# ADSP-SC83xW_HPC register map
Vendor: Analog Devices; Series: ADSP-SC83xW_HPC; File version: 3.0.3.517
CPU: 
Registers are 32-bit, read-write, reset 0x0 unless marked. A register's access mark holds for its fields unless they carry their own. Offsets are from the block's base; [hi:lo] are bit positions; {n}, {i} and the like mark numbered series.

## EMAC0 (part 2 of 4) — RGMII, RMII, MII Ethernet Controller
Base 0x31040000
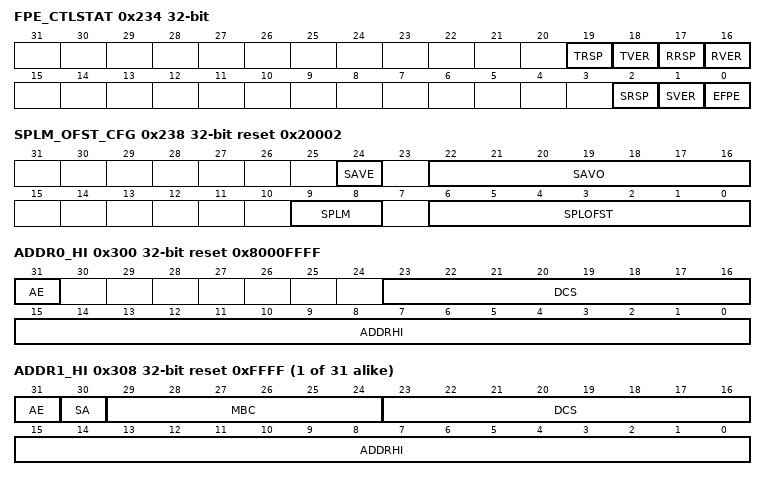
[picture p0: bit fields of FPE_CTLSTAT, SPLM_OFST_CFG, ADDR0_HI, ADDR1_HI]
0x234 FPE_CTLSTAT — Frame Preemption Control and Status Register
  [19] TRSP — Transmitted Respond Frame
    0=TRSP_INACTIVE (Not Transmitted Respond Frame); 1=TRSP_ACTIVE (Transmitted Respond Frame)
  [18] TVER — Transmitted Verify Frame
    0=TVER_INACTIVE (Not Transmitted Verify Frame); 1=TVER_ACTIVE (Transmitted Verify Frame)
  [17] RRSP — Received Respond Frame
    0=RRSP_INACTIVE (Not Received Respond Frame); 1=RRSP_ACTIVE (Received Respond Frame)
  [16] RVER — Received Verify Frame
    0=RVER_INACTIVE (Not Received Verify Frame); 1=RVER_ACTIVE (Received Verify Frame)
  [2] SRSP — Send Respond mPacket
    0=SRSP_DISABLE (Send Respond MPacket is Disabled); 1=SRSP_ENABLE (Send Respond MPacket is Enabled)
  [1] SVER — Send Verify mPacket
    0=SVER_DISABLE (Send Verify MPacket is Disabled); 1=SVER_ENABLE (Send Verify MPacket is Enabled)
  [0] EFPE — Enable Tx Frame Preemption
    0=EFPE_DISABLE (Tx Frame Preemption is Disabled); 1=EFPE_ENABLE (Tx Frame Preemption is Enabled)
0x238 SPLM_OFST_CFG reset 0x20002 — MAC Split Mode and Offset Configuration Register
  [24] SAVE range 0x00000000..0x00000001 — Split AV Enable
  [22:16] SAVO range 0x00000000..0x0000007F — Split AV Offset
  [9:8] SPLM — Split Mode
    0=L3L4 (Split at L3/L4 Header); 1=L2OFST (Split at L2 Header with an Offset. Always Split at SPLOFST Bytes from the Beginning of Length/Type Field of the Frame); 2=COMBN (Combination Mode: Split Similar to SPLM=00 for IP Packets That are Untagged or Tagged and VLAN Stripped)
  [6:0] SPLOFST range 0x00000000..0x0000007F — Split Offset
0x240 PRSNTM_NSEC — Presentation Time Nanosecond Register
  [31:0] MPTN ro — 1722 Presentation Time in Nanoseconds
0x244 PRSNTM_UPDT — Presentation Time Update Register
  [31:0] MPTU range 0x00000000..0xFFFFFFFF — 1722 Presentation Time Update
0x300 ADDR0_HI reset 0x8000FFFF — MAC Address 0 High Register
  [31] AE ro — Address Enable
    0=AE_DISABLE (Invalid); 1=AE_ENABLE (The bit is always set)
  [23:16] DCS range 0x00000000..0x000000FF — DMA Channel Select
  [15:0] ADDRHI range 0x00000000..0x0000FFFF — MAC address 0[47:32]
0x304 ADDR0_LO reset 0xFFFFFFFF — MAC Address 0 Low Register
  [31:0] ADDRLO range 0x00000000..0xFFFFFFFF — MAC Address0[31:0]
{0x300+8i} ADDR{i}_HI reset 0xFFFF (i=1..31) — MAC Address n High Register
  [31] AE — Address Enable
    0=AE_DISABLE (Address is Ignored); 1=AE_ENABLE (Address is Enabled)
  [30] SA — Source Address
    0=DA (Compare with Destination Address); 1=SA (Compare with Source Address)
  [29:24] MBC range 0x00000000..0x0000003F — Mask Byte Control
  [23:16] DCS range 0x00000000..0x000000FF — DMA Channel Select
  [15:0] ADDRHI range 0x00000000..0x0000FFFF — MAC Address1 [47:32]
{0x304+8i} ADDR{i}_LO reset 0xFFFFFFFF (i=1..31) — MAC Address n Low Register
  [31:0] ADDRLO range 0x00000000..0xFFFFFFFF — MAC Address1 [31:0]
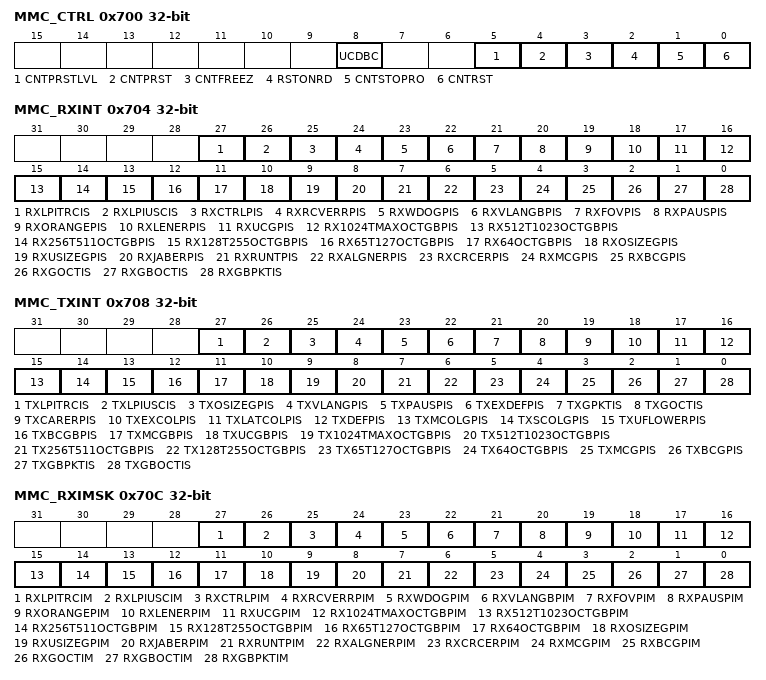
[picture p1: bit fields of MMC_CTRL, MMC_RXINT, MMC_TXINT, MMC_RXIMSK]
0x700 MMC_CTRL — MMC Control Register
  [8] UCDBC — Update MMC Counters for Dropped Broadcast Packets
    0=UCDBC_DISABLE (Update MMC Counters for Dropped Broadcast Packets is Disabled); 1=UCDBC_ENABLE (Update MMC Counters for Dropped Broadcast Packets is Enabled)
  [5] CNTPRSTLVL — Full-Half Preset
    0=CNTPRSTLVL_DISABLE (Full-Half Preset is Disabled); 1=CNTPRSTLVL_ENABLE (Full-Half Preset is Enabled)
  [4] CNTPRST — Counters Preset
    0=CNTPRST_DISABLE (Counters Preset is Disabled); 1=CNTPRST_ENABLE (Counters Preset is Enabled)
  [3] CNTFREEZ — MMC Counter Freeze
    0=CNTFREEZ_DISABLE (MMC Counter Freeze is Disabled); 1=CNTFREEZ_ENABLE (MMC Counter Freeze is Enabled)
  [2] RSTONRD — Reset on Read
    0=RSTONRD_DISABLE (Reset on Read is Disabled); 1=RSTONRD_ENABLE (Reset on Read is Enabled)
  [1] CNTSTOPRO — Counter Stop Rollover
    0=CNTSTOPRO_DISABLE (Counter Stop Rollover is Disabled); 1=CNTSTOPRO_ENABLE (Counter Stop Rollover is Enabled)
  [0] CNTRST — Counters Reset
    0=CNTRST_DISABLE (Counters are Not Reset); 1=CNTRST_ENABLE (All Counters are Reset)
0x704 MMC_RXINT — MMC Receive Interrupt Status Register
  [27] RXLPITRCIS ro — MMC Receive LPI Transition Counter Interrupt Status
    0=RXLPITRCIS_INACTIVE (MMC Receive LPI Transition Counter Interrupt Status Not Detected); 1=RXLPITRCIS_ACTIVE (MMC Receive LPI Transition Counter Interrupt Status Detected)
  [26] RXLPIUSCIS ro — MMC Receive LPI Microsecond Counter Interrupt Status
    0=RXLPIUSCIS_INACTIVE (MMC Receive LPI Microsecond Counter Interrupt Status Not Detected); 1=RXLPIUSCIS_ACTIVE (MMC Receive LPI Microsecond Counter Interrupt Status Detected)
  [25] RXCTRLPIS ro — MMC Receive Control Packet Counter Interrupt Status
    0=RXCTRLPIS_INACTIVE (MMC Receive Control Packet Counter Interrupt Status Not Detected); 1=RXCTRLPIS_ACTIVE (MMC Receive Control Packet Counter Interrupt Status Detected)
  [24] RXRCVERRPIS ro — MMC Receive Error Packet Counter Interrupt Status
    0=RXRCVERRPIS_INACTIVE (MMC Receive Error Packet Counter Interrupt Status Not Detected); 1=RXRCVERRPIS_ACTIVE (MMC Receive Error Packet Counter Interrupt Status Detected)
  [23] RXWDOGPIS ro — MMC Receive Watchdog Error Packet Counter Interrupt Status
    0=RXWDOGPIS_INACTIVE (MMC Receive Watchdog Error Packet Counter Interrupt Status Not Detected); 1=RXWDOGPIS_ACTIVE (MMC Receive Watchdog Error Packet Counter Interrupt Status Detected)
  [22] RXVLANGBPIS ro — MMC Receive VLAN Good Bad Packet Counter Interrupt Status
    0=RXVLANGBPIS_INACTIVE (MMC Receive VLAN Good Bad Packet Counter Interrupt Status Not Detected); 1=RXVLANGBPIS_ACTIVE (MMC Receive VLAN Good Bad Packet Counter Interrupt Status Detected)
  [21] RXFOVPIS ro — MMC Receive FIFO Overflow Packet Counter Interrupt Status
    0=RXFOVPIS_INACTIVE (MMC Receive FIFO Overflow Packet Counter Interrupt Status Not Detected); 1=RXFOVPIS_ACTIVE (MMC Receive FIFO Overflow Packet Counter Interrupt Status Detected)
  [20] RXPAUSPIS ro — MMC Receive Pause Packet Counter Interrupt Status
    0=RXPAUSPIS_INACTIVE (MMC Receive Pause Packet Counter Interrupt Status Not Detected); 1=RXPAUSPIS_ACTIVE (MMC Receive Pause Packet Counter Interrupt Status Detected)
  [19] RXORANGEPIS ro — MMC Receive Out of Range Error Packet Counter Interrupt Status.
    0=RXORANGEPIS_INACTIVE (MMC Receive Out of Range Error Packet Counter Interrupt Status Not Detected); 1=RXORANGEPIS_ACTIVE (MMC Receive Out of Range Error Packet Counter Interrupt Status Detected)
  [18] RXLENERPIS ro — MMC Receive Length Error Packet Counter Interrupt Status
    0=RXLENERPIS_INACTIVE (MMC Receive Length Error Packet Counter Interrupt Status Not Detected); 1=RXLENERPIS_ACTIVE (MMC Receive Length Error Packet Counter Interrupt Status Detected)
  [17] RXUCGPIS ro — MMC Receive Unicast Good Packet Counter Interrupt Status
    0=RXUCGPIS_INACTIVE (MMC Receive Unicast Good Packet Counter Interrupt Status Not Detected); 1=RXUCGPIS_ACTIVE (MMC Receive Unicast Good Packet Counter Interrupt Status Detected)
  [16] RX1024TMAXOCTGBPIS ro — MMC Receive 1024 to Maximum Octet Good Bad Packet Counter Interrupt Status
    0=RX1024TMAXOCTGBPIS_INACTIVE (MMC Receive 1024 to Maximum Octet Good Bad Packet Counter Interrupt Status Not Detected); 1=RX1024TMAXOCTGBPIS_ACTIVE (MMC Receive 1024 to Maximum Octet Good Bad Packet Counter Interrupt Status Detected)
  [15] RX512T1023OCTGBPIS ro — MMC Receive 512 to 1023 Octet Good Bad Packet Counter Interrupt Status
    0=RX512T1023OCTGBPIS_INACTIVE (MMC Receive 512 to 1023 Octet Good Bad Packet Counter Interrupt Status Not Detected); 1=RX512T1023OCTGBPIS_ACTIVE (MMC Receive 512 to 1023 Octet Good Bad Packet Counter Interrupt Status Detected)
  [14] RX256T511OCTGBPIS ro — MMC Receive 256 to 511 Octet Good Bad Packet Counter Interrupt Status
    0=RX256T511OCTGBPIS_INACTIVE (MMC Receive 256 to 511 Octet Good Bad Packet Counter Interrupt Status Not Detected); 1=RX256T511OCTGBPIS_ACTIVE (MMC Receive 256 to 511 Octet Good Bad Packet Counter Interrupt Status Detected)
  [13] RX128T255OCTGBPIS ro — MMC Receive 128 to 255 Octet Good Bad Packet Counter Interrupt Status
    0=RX128T255OCTGBPIS_INACTIVE (MMC Receive 128 to 255 Octet Good Bad Packet Counter Interrupt Status Not Detected); 1=RX128T255OCTGBPIS_ACTIVE (MMC Receive 128 to 255 Octet Good Bad Packet Counter Interrupt Status Detected)
  [12] RX65T127OCTGBPIS ro — MMC Receive 65 to 127 Octet Good Bad Packet Counter Interrupt Status
    0=RX65T127OCTGBPIS_INACTIVE (MMC Receive 65 to 127 Octet Good Bad Packet Counter Interrupt Status Not Detected); 1=RX65T127OCTGBPIS_ACTIVE (MMC Receive 65 to 127 Octet Good Bad Packet Counter Interrupt Status Detected)
  [11] RX64OCTGBPIS ro — MMC Receive 64 Octet Good Bad Packet Counter Interrupt Status
    0=RX64OCTGBPIS_INACTIVE (MMC Receive 64 Octet Good Bad Packet Counter Interrupt Status Not Detected); 1=RX64OCTGBPIS_ACTIVE (MMC Receive 64 Octet Good Bad Packet Counter Interrupt Status Detected)
  [10] RXOSIZEGPIS ro — MMC Receive Oversize Good Packet Counter Interrupt Status
    0=RXOSIZEGPIS_INACTIVE (MMC Receive Oversize Good Packet Counter Interrupt Status Not Detected); 1=RXOSIZEGPIS_ACTIVE (MMC Receive Oversize Good Packet Counter Interrupt Status Detected)
  [9] RXUSIZEGPIS ro — MMC Receive Undersize Good Packet Counter Interrupt Status
    0=RXUSIZEGPIS_INACTIVE (MMC Receive Undersize Good Packet Counter Interrupt Status Not Detected); 1=RXUSIZEGPIS_ACTIVE (MMC Receive Undersize Good Packet Counter Interrupt Status Detected)
  [8] RXJABERPIS ro — MMC Receive Jabber Error Packet Counter Interrupt Status
    0=RXJABERPIS_INACTIVE (MMC Receive Jabber Error Packet Counter Interrupt Status Not Detected); 1=RXJABERPIS_ACTIVE (MMC Receive Jabber Error Packet Counter Interrupt Status Detected)
  [7] RXRUNTPIS ro — MMC Receive Runt Packet Counter Interrupt Status
    0=RXRUNTPIS_INACTIVE (MMC Receive Runt Packet Counter Interrupt Status Not Detected); 1=RXRUNTPIS_ACTIVE (MMC Receive Runt Packet Counter Interrupt Status Detected)
  [6] RXALGNERPIS ro — MMC Receive Alignment Error Packet Counter Interrupt Status
    0=RXALGNERPIS_INACTIVE (MMC Receive Alignment Error Packet Counter Interrupt Status Not Detected); 1=RXALGNERPIS_ACTIVE (MMC Receive Alignment Error Packet Counter Interrupt Status Detected)
  [5] RXCRCERPIS ro — MMC Receive CRC Error Packet Counter Interrupt Status
    0=RXCRCERPIS_INACTIVE (MMC Receive CRC Error Packet Counter Interrupt Status Not Detected); 1=RXCRCERPIS_ACTIVE (MMC Receive CRC Error Packet Counter Interrupt Status Detected)
  [4] RXMCGPIS ro — MMC Receive Multicast Good Packet Counter Interrupt Status
    0=RXMCGPIS_INACTIVE (MMC Receive Multicast Good Packet Counter Interrupt Status Not Detected); 1=RXMCGPIS_ACTIVE (MMC Receive Multicast Good Packet Counter Interrupt Status Detected)
  [3] RXBCGPIS ro — MMC Receive Broadcast Good Packet Counter Interrupt Status
    0=RXBCGPIS_INACTIVE (MMC Receive Broadcast Good Packet Counter Interrupt Status Not Detected); 1=RXBCGPIS_ACTIVE (MMC Receive Broadcast Good Packet Counter Interrupt Status Detected)
  [2] RXGOCTIS ro — MMC Receive Good Octet Counter Interrupt Status
    0=RXGOCTIS_INACTIVE (MMC Receive Good Octet Counter Interrupt Status Not Detected); 1=RXGOCTIS_ACTIVE (MMC Receive Good Octet Counter Interrupt Status Detected)
  [1] RXGBOCTIS ro — MMC Receive Good Bad Octet Counter Interrupt Status
    0=RXGBOCTIS_INACTIVE (MMC Receive Good Bad Octet Counter Interrupt Status Not Detected); 1=RXGBOCTIS_ACTIVE (MMC Receive Good Bad Octet Counter Interrupt Status Detected)
  [0] RXGBPKTIS ro — MMC Receive Good Bad Packet Counter Interrupt Status
    0=RXGBPKTIS_INACTIVE (MMC Receive Good Bad Packet Counter Interrupt Status Not Detected); 1=RXGBPKTIS_ACTIVE (MMC Receive Good Bad Packet Counter Interrupt Status Detected)
0x708 MMC_TXINT — MMC Transmit Interrupt Status Register
  [27] TXLPITRCIS ro — MMC Transmit LPI Transition Counter Interrupt Status
    0=TXLPITRCIS_INACTIVE (MMC Transmit LPI Transition Counter Interrupt Status Not Detected); 1=TXLPITRCIS_ACTIVE (MMC Transmit LPI Transition Counter Interrupt Status Detected)
  [26] TXLPIUSCIS ro — MMC Transmit LPI Microsecond Counter Interrupt Status
    0=TXLPIUSCIS_INACTIVE (MMC Transmit LPI Microsecond Counter Interrupt Status Not Detected); 1=TXLPIUSCIS_ACTIVE (MMC Transmit LPI Microsecond Counter Interrupt Status Detected)
  [25] TXOSIZEGPIS ro — MMC Transmit Oversize Good Packet Counter Interrupt Status
    0=TXOSIZEGPIS_INACTIVE (MMC Transmit Oversize Good Packet Counter Interrupt Status Not Detected); 1=TXOSIZEGPIS_ACTIVE (MMC Transmit Oversize Good Packet Counter Interrupt Status Detected)
  [24] TXVLANGPIS ro — MMC Transmit VLAN Good Packet Counter Interrupt Status
    0=TXVLANGPIS_INACTIVE (MMC Transmit VLAN Good Packet Counter Interrupt Status Not Detected); 1=TXVLANGPIS_ACTIVE (MMC Transmit VLAN Good Packet Counter Interrupt Status Detected)
  [23] TXPAUSPIS ro — MMC Transmit Pause Packet Counter Interrupt Status
    0=TXPAUSPIS_INACTIVE (MMC Transmit Pause Packet Counter Interrupt Status Not Detected); 1=TXPAUSPIS_ACTIVE (MMC Transmit Pause Packet Counter Interrupt Status Detected)
  [22] TXEXDEFPIS ro — MMC Transmit Excessive Deferral Packet Counter Interrupt Status
    0=TXEXDEFPIS_INACTIVE (MMC Transmit Excessive Deferral Packet Counter Interrupt Status Not Detected); 1=TXEXDEFPIS_ACTIVE (MMC Transmit Excessive Deferral Packet Counter Interrupt Status Detected)
  [21] TXGPKTIS ro — MMC Transmit Good Packet Counter Interrupt Status
    0=TXGPKTIS_INACTIVE (MMC Transmit Good Packet Counter Interrupt Status Not Detected); 1=TXGPKTIS_ACTIVE (MMC Transmit Good Packet Counter Interrupt Status Detected)
  [20] TXGOCTIS ro — MMC Transmit Good Octet Counter Interrupt Status
    0=TXGOCTIS_INACTIVE (MMC Transmit Good Octet Counter Interrupt Status Not Detected); 1=TXGOCTIS_ACTIVE (MMC Transmit Good Octet Counter Interrupt Status Detected)
  [19] TXCARERPIS ro — MMC Transmit Carrier Error Packet Counter Interrupt Status
    0=TXCARERPIS_INACTIVE (MMC Transmit Carrier Error Packet Counter Interrupt Status Not Detected); 1=TXCARERPIS_ACTIVE (MMC Transmit Carrier Error Packet Counter Interrupt Status Detected)
  [18] TXEXCOLPIS ro — MMC Transmit Excessive Collision Packet Counter Interrupt Status
    0=TXEXCOLPIS_INACTIVE (MMC Transmit Excessive Collision Packet Counter Interrupt Status Not Detected); 1=TXEXCOLPIS_ACTIVE (MMC Transmit Excessive Collision Packet Counter Interrupt Status Detected)
  [17] TXLATCOLPIS ro — MMC Transmit Late Collision Packet Counter Interrupt Status
    0=TXLATCOLPIS_INACTIVE (MMC Transmit Late Collision Packet Counter Interrupt Status Not Detected); 1=TXLATCOLPIS_ACTIVE (MMC Transmit Late Collision Packet Counter Interrupt Status Detected)
  [16] TXDEFPIS ro — MMC Transmit Deferred Packet Counter Interrupt Status
    0=TXDEFPIS_INACTIVE (MMC Transmit Deferred Packet Counter Interrupt Status Not Detected); 1=TXDEFPIS_ACTIVE (MMC Transmit Deferred Packet Counter Interrupt Status Detected)
  [15] TXMCOLGPIS ro — MMC Transmit Multiple Collision Good Packet Counter Interrupt Status
    0=TXMCOLGPIS_INACTIVE (MMC Transmit Multiple Collision Good Packet Counter Interrupt Status Not Detected); 1=TXMCOLGPIS_ACTIVE (MMC Transmit Multiple Collision Good Packet Counter Interrupt Status Detected)
  [14] TXSCOLGPIS ro — MMC Transmit Single Collision Good Packet Counter Interrupt Status
    0=TXSCOLGPIS_INACTIVE (MMC Transmit Single Collision Good Packet Counter Interrupt Status Not Detected); 1=TXSCOLGPIS_ACTIVE (MMC Transmit Single Collision Good Packet Counter Interrupt Status Detected)
  [13] TXUFLOWERPIS ro — MMC Transmit Underflow Error Packet Counter Interrupt Status
    0=TXUFLOWERPIS_INACTIVE (MMC Transmit Underflow Error Packet Counter Interrupt Status Not Detected); 1=TXUFLOWERPIS_ACTIVE (MMC Transmit Underflow Error Packet Counter Interrupt Status Detected)
  [12] TXBCGBPIS ro — MMC Transmit Broadcast Good Bad Packet Counter Interrupt Status
    0=TXBCGBPIS_INACTIVE (MMC Transmit Broadcast Good Bad Packet Counter Interrupt Status Not Detected); 1=TXBCGBPIS_ACTIVE (MMC Transmit Broadcast Good Bad Packet Counter Interrupt Status Detected)
  [11] TXMCGBPIS ro — MMC Transmit Multicast Good Bad Packet Counter Interrupt Status
    0=TXMCGBPIS_INACTIVE (MMC Transmit Multicast Good Bad Packet Counter Interrupt Status Not Detected); 1=TXMCGBPIS_ACTIVE (MMC Transmit Multicast Good Bad Packet Counter Interrupt Status Detected)
  [10] TXUCGBPIS ro — MMC Transmit Unicast Good Bad Packet Counter Interrupt Status
    0=TXUCGBPIS_INACTIVE (MMC Transmit Unicast Good Bad Packet Counter Interrupt Status Not Detected); 1=TXUCGBPIS_ACTIVE (MMC Transmit Unicast Good Bad Packet Counter Interrupt Status Detected)
  [9] TX1024TMAXOCTGBPIS ro — MMC Transmit 1024 to Maximum Octet Good Bad Packet Counter Interrupt Status
    0=TX1024TMAXOCTGBPIS_INACTIVE (MMC Transmit 1024 to Maximum Octet Good Bad Packet Counter Interrupt Status Not Detected); 1=TX1024TMAXOCTGBPIS_ACTIVE (MMC Transmit 1024 to Maximum Octet Good Bad Packet Counter Interrupt Status Detected)
  [8] TX512T1023OCTGBPIS ro — MMC Transmit 512 to 1023 Octet Good Bad Packet Counter Interrupt Status
    0=TX512T1023OCTGBPIS_INACTIVE (MMC Transmit 512 to 1023 Octet Good Bad Packet Counter Interrupt Status Not Detected); 1=TX512T1023OCTGBPIS_ACTIVE (MMC Transmit 512 to 1023 Octet Good Bad Packet Counter Interrupt Status Detected)
  [7] TX256T511OCTGBPIS ro — MMC Transmit 256 to 511 Octet Good Bad Packet Counter Interrupt Status
    0=TX256T511OCTGBPIS_INACTIVE (MMC Transmit 256 to 511 Octet Good Bad Packet Counter Interrupt Status Not Detected); 1=TX256T511OCTGBPIS_ACTIVE (MMC Transmit 256 to 511 Octet Good Bad Packet Counter Interrupt Status Detected)
  [6] TX128T255OCTGBPIS ro — MMC Transmit 128 to 255 Octet Good Bad Packet Counter Interrupt Status
    0=TX128T255OCTGBPIS_INACTIVE (MMC Transmit 128 to 255 Octet Good Bad Packet Counter Interrupt Status Not Detected); 1=TX128T255OCTGBPIS_ACTIVE (MMC Transmit 128 to 255 Octet Good Bad Packet Counter Interrupt Status Detected)
  [5] TX65T127OCTGBPIS ro — MMC Transmit 65 to 127 Octet Good Bad Packet Counter Interrupt Status
    0=TX65T127OCTGBPIS_INACTIVE (MMC Transmit 65 to 127 Octet Good Bad Packet Counter Interrupt Status Not Detected); 1=TX65T127OCTGBPIS_ACTIVE (MMC Transmit 65 to 127 Octet Good Bad Packet Counter Interrupt Status Detected)
  [4] TX64OCTGBPIS ro — MMC Transmit 64 Octet Good Bad Packet Counter Interrupt Status
    0=TX64OCTGBPIS_INACTIVE (MMC Transmit 64 Octet Good Bad Packet Counter Interrupt Status Not Detected); 1=TX64OCTGBPIS_ACTIVE (MMC Transmit 64 Octet Good Bad Packet Counter Interrupt Status Detected)
  [3] TXMCGPIS ro — MMC Transmit Multicast Good Packet Counter Interrupt Status
    0=TXMCGPIS_INACTIVE (MMC Transmit Multicast Good Packet Counter Interrupt Status Not Detected); 1=TXMCGPIS_ACTIVE (MMC Transmit Multicast Good Packet Counter Interrupt Status Detected)
  [2] TXBCGPIS ro — MMC Transmit Broadcast Good Packet Counter Interrupt Status
    0=TXBCGPIS_INACTIVE (MMC Transmit Broadcast Good Packet Counter Interrupt Status Not Detected); 1=TXBCGPIS_ACTIVE (MMC Transmit Broadcast Good Packet Counter Interrupt Status Detected)
  [1] TXGBPKTIS ro — MMC Transmit Good Bad Packet Counter Interrupt Status
    0=TXGBPKTIS_INACTIVE (MMC Transmit Good Bad Packet Counter Interrupt Status Not Detected); 1=TXGBPKTIS_ACTIVE (MMC Transmit Good Bad Packet Counter Interrupt Status Detected)
  [0] TXGBOCTIS ro — MMC Transmit Good Bad Octet Counter Interrupt Status
    0=TXGBOCTIS_INACTIVE (MMC Transmit Good Bad Octet Counter Interrupt Status Not Detected); 1=TXGBOCTIS_ACTIVE (MMC Transmit Good Bad Octet Counter Interrupt Status Detected)
0x70C MMC_RXIMSK — MMC Receive Interrupt Mask Register
  [27] RXLPITRCIM — MMC Receive LPI Transition Counter Interrupt Mask
    0=RXLPITRCIM_DISABLE (MMC Receive LPI Transition Counter Interrupt Mask is Disabled); 1=RXLPITRCIM_ENABLE (MMC Receive LPI Transition Counter Interrupt Mask is Enabled)
  [26] RXLPIUSCIM — MMC Receive LPI Microsecond Counter Interrupt Mask
    0=RXLPIUSCIM_DISABLE (MMC Receive LPI Microsecond Counter Interrupt Mask is Disabled); 1=RXLPIUSCIM_ENABLE (MMC Receive LPI Microsecond Counter Interrupt Mask is Enabled)
  [25] RXCTRLPIM — MMC Receive Control Packet Counter Interrupt Mask
    0=RXCTRLPIM_DISABLE (MMC Receive Control Packet Counter Interrupt Mask is Disabled); 1=RXCTRLPIM_ENABLE (MMC Receive Control Packet Counter Interrupt Mask is Enabled)
  [24] RXRCVERRPIM — MMC Receive Error Packet Counter Interrupt Mask
    0=RXRCVERRPIM_DISABLE (MMC Receive Error Packet Counter Interrupt Mask is Disabled); 1=RXRCVERRPIM_ENABLE (MMC Receive Error Packet Counter Interrupt Mask is Enabled)
  [23] RXWDOGPIM — MMC Receive Watchdog Error Packet Counter Interrupt Mask
    0=RXWDOGPIM_DISABLE (MMC Receive Watchdog Error Packet Counter Interrupt Mask is Disabled); 1=RXWDOGPIM_ENABLE (MMC Receive Watchdog Error Packet Counter Interrupt Mask is Enabled)
  [22] RXVLANGBPIM — MMC Receive VLAN Good Bad Packet Counter Interrupt Mask
    0=RXVLANGBPIM_DISABLE (MMC Receive VLAN Good Bad Packet Counter Interrupt Mask is Disabled); 1=RXVLANGBPIM_ENABLE (MMC Receive VLAN Good Bad Packet Counter Interrupt Mask is Enabled)
  [21] RXFOVPIM — MMC Receive FIFO Overflow Packet Counter Interrupt Mask
    0=RXFOVPIM_DISABLE (MMC Receive FIFO Overflow Packet Counter Interrupt Mask is Disabled); 1=RXFOVPIM_ENABLE (MMC Receive FIFO Overflow Packet Counter Interrupt Mask is Enabled)
  [20] RXPAUSPIM — MMC Receive Pause Packet Counter Interrupt Mask
    0=RXPAUSPIM_DISABLE (MMC Receive Pause Packet Counter Interrupt Mask is Disabled); 1=RXPAUSPIM_ENABLE (MMC Receive Pause Packet Counter Interrupt Mask is Enabled)
  [19] RXORANGEPIM — MMC Receive Out of Range Error Packet Counter Interrupt Mask
    0=RXORANGEPIM_DISABLE (MMC Receive Out of Range Error Packet Counter Interrupt Mask is Disabled); 1=RXORANGEPIM_ENABLE (MMC Receive Out of Range Error Packet Counter Interrupt Mask is Enabled)
  [18] RXLENERPIM — MMC Receive Length Error Packet Counter Interrupt Mask
    0=RXLENERPIM_DISABLE (MMC Receive Length Error Packet Counter Interrupt Mask is Disabled); 1=RXLENERPIM_ENABLE (MMC Receive Length Error Packet Counter Interrupt Mask is Enabled)
  [17] RXUCGPIM — MMC Receive Unicast Good Packet Counter Interrupt Mask
    0=RXUCGPIM_DISABLE (MMC Receive Unicast Good Packet Counter Interrupt Mask is Disabled); 1=RXUCGPIM_ENABLE (MMC Receive Unicast Good Packet Counter Interrupt Mask is Enabled)
  [16] RX1024TMAXOCTGBPIM — MMC Receive 1024 to Maximum Octet Good Bad Packet Counter Interrupt Mask.
    0=RX1024TMAXOCTGBPIM_DISABLE (MMC Receive 1024 to Maximum Octet Good Bad Packet Counter Interrupt Mask is Disabled); 1=RX1024TMAXOCTGBPIM_ENABLE (MMC Receive 1024 to Maximum Octet Good Bad Packet Counter Interrupt Mask is Enabled)
  [15] RX512T1023OCTGBPIM — MMC Receive 512 to 1023 Octet Good Bad Packet Counter Interrupt Mask
    0=RX512T1023OCTGBPIM_DISABLE (MMC Receive 512 to 1023 Octet Good Bad Packet Counter Interrupt Mask is Disabled); 1=RX512T1023OCTGBPIM_ENABLE (MMC Receive 512 to 1023 Octet Good Bad Packet Counter Interrupt Mask is Enabled)
  [14] RX256T511OCTGBPIM — MMC Receive 256 to 511 Octet Good Bad Packet Counter Interrupt Mask
    0=RX256T511OCTGBPIM_DISABLE (MMC Receive 256 to 511 Octet Good Bad Packet Counter Interrupt Mask is Disabled); 1=RX256T511OCTGBPIM_ENABLE (MMC Receive 256 to 511 Octet Good Bad Packet Counter Interrupt Mask is Enabled)
  [13] RX128T255OCTGBPIM — MMC Receive 128 to 255 Octet Good Bad Packet Counter Interrupt Mask
    0=RX128T255OCTGBPIM_DISABLE (MMC Receive 128 to 255 Octet Good Bad Packet Counter Interrupt Mask is Disabled); 1=RX128T255OCTGBPIM_ENABLE (MMC Receive 128 to 255 Octet Good Bad Packet Counter Interrupt Mask is Enabled)
  [12] RX65T127OCTGBPIM — MMC Receive 65 to 127 Octet Good Bad Packet Counter Interrupt Mask
    0=RX65T127OCTGBPIM_DISABLE (MMC Receive 65 to 127 Octet Good Bad Packet Counter Interrupt Mask is Disabled); 1=RX65T127OCTGBPIM_ENABLE (MMC Receive 65 to 127 Octet Good Bad Packet Counter Interrupt Mask is Enabled)
  [11] RX64OCTGBPIM — MMC Receive 64 Octet Good Bad Packet Counter Interrupt Mask
    0=RX64OCTGBPIM_DISABLE (MMC Receive 64 Octet Good Bad Packet Counter Interrupt Mask is Disabled); 1=RX64OCTGBPIM_ENABLE (MMC Receive 64 Octet Good Bad Packet Counter Interrupt Mask is Enabled)
  [10] RXOSIZEGPIM — MMC Receive Oversize Good Packet Counter Interrupt Mask
    0=RXOSIZEGPIM_DISABLE (MMC Receive Oversize Good Packet Counter Interrupt Mask is Disabled); 1=RXOSIZEGPIM_ENABLE (MMC Receive Oversize Good Packet Counter Interrupt Mask is Enabled)
  [9] RXUSIZEGPIM — MMC Receive Undersize Good Packet Counter Interrupt Mask
    0=RXUSIZEGPIM_DISABLE (MMC Receive Undersize Good Packet Counter Interrupt Mask is Disabled); 1=RXUSIZEGPIM_ENABLE (MMC Receive Undersize Good Packet Counter Interrupt Mask is Enabled)
  [8] RXJABERPIM — MMC Receive Jabber Error Packet Counter Interrupt Mask
    0=RXJABERPIM_DISABLE (MMC Receive Jabber Error Packet Counter Interrupt Mask is Disabled); 1=RXJABERPIM_ENABLE (MMC Receive Jabber Error Packet Counter Interrupt Mask is Enabled)
  [7] RXRUNTPIM — MMC Receive Runt Packet Counter Interrupt Mask
    0=RXRUNTPIM_DISABLE (MMC Receive Runt Packet Counter Interrupt Mask is Disabled); 1=RXRUNTPIM_ENABLE (MMC Receive Runt Packet Counter Interrupt Mask is Enabled)
  [6] RXALGNERPIM — MMC Receive Alignment Error Packet Counter Interrupt Mask
    0=RXALGNERPIM_DISABLE (MMC Receive Alignment Error Packet Counter Interrupt Mask is Disabled); 1=RXALGNERPIM_ENABLE (MMC Receive Alignment Error Packet Counter Interrupt Mask is Enabled)
  [5] RXCRCERPIM — MMC Receive CRC Error Packet Counter Interrupt Mask
    0=RXCRCERPIM_DISABLE (MMC Receive CRC Error Packet Counter Interrupt Mask is Disabled); 1=RXCRCERPIM_ENABLE (MMC Receive CRC Error Packet Counter Interrupt Mask is Enabled)
  [4] RXMCGPIM — MMC Receive Multicast Good Packet Counter Interrupt Mask
    0=RXMCGPIM_DISABLE (MMC Receive Multicast Good Packet Counter Interrupt Mask is Disabled); 1=RXMCGPIM_ENABLE (MMC Receive Multicast Good Packet Counter Interrupt Mask is Enabled)
  [3] RXBCGPIM — MMC Receive Broadcast Good Packet Counter Interrupt Mask
    0=RXBCGPIM_DISABLE (MMC Receive Broadcast Good Packet Counter Interrupt Mask is Disabled); 1=RXBCGPIM_ENABLE (MMC Receive Broadcast Good Packet Counter Interrupt Mask is Enabled)
  [2] RXGOCTIM — MMC Receive Good Octet Counter Interrupt Mask
    0=RXGOCTIM_DISABLE (MMC Receive Good Octet Counter Interrupt Mask is Disabled); 1=RXGOCTIM_ENABLE (MMC Receive Good Octet Counter Interrupt Mask is Enabled)
  [1] RXGBOCTIM — MMC Receive Good Bad Octet Counter Interrupt Mask
    0=RXGBOCTIM_DISABLE (MMC Receive Good Bad Octet Counter Interrupt Mask is Disabled); 1=RXGBOCTIM_ENABLE (MMC Receive Good Bad Octet Counter Interrupt Mask is Enabled)
  [0] RXGBPKTIM — MMC Receive Good Bad Packet Counter Interrupt Mask
    0=RXGBPKTIM_DISABLE (MMC Receive Good Bad Packet Counter Interrupt Mask is Disabled); 1=RXGBPKTIM_ENABLE (MMC Receive Good Bad Packet Counter Interrupt Mask is Enabled)
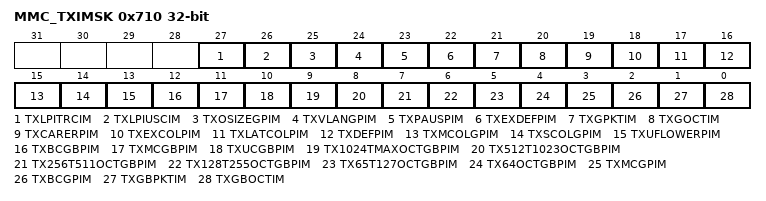
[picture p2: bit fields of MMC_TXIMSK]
0x710 MMC_TXIMSK — MMC Transmit Interrupt Mask Register
  [27] TXLPITRCIM — MMC Transmit LPI Transition Counter Interrupt Mask
    0=TXLPITRCIM_DISABLE (MMC Transmit LPI Transition Counter Interrupt Mask is Disabled); 1=TXLPITRCIM_ENABLE (MMC Transmit LPI Transition Counter Interrupt Mask is Enabled)
  [26] TXLPIUSCIM — MMC Transmit LPI Microsecond Counter Interrupt Mask
    0=TXLPIUSCIM_DISABLE (MMC Transmit LPI Microsecond Counter Interrupt Mask is Disabled); 1=TXLPIUSCIM_ENABLE (MMC Transmit LPI Microsecond Counter Interrupt Mask is Enabled)
  [25] TXOSIZEGPIM — MMC Transmit Oversize Good Packet Counter Interrupt Mask
    0=TXOSIZEGPIM_DISABLE (MMC Transmit Oversize Good Packet Counter Interrupt Mask is Disabled); 1=TXOSIZEGPIM_ENABLE (MMC Transmit Oversize Good Packet Counter Interrupt Mask is Enabled)
  [24] TXVLANGPIM — MMC Transmit VLAN Good Packet Counter Interrupt Mask
    0=TXVLANGPIM_DISABLE (MMC Transmit VLAN Good Packet Counter Interrupt Mask is Disabled); 1=TXVLANGPIM_ENABLE (MMC Transmit VLAN Good Packet Counter Interrupt Mask is Enabled)
  [23] TXPAUSPIM — MMC Transmit Pause Packet Counter Interrupt Mask
    0=TXPAUSPIM_DISABLE (MMC Transmit Pause Packet Counter Interrupt Mask is Disabled); 1=TXPAUSPIM_ENABLE (MMC Transmit Pause Packet Counter Interrupt Mask is Enabled)
  [22] TXEXDEFPIM — MMC Transmit Excessive Deferral Packet Counter Interrupt Mask
    0=TXEXDEFPIM_DISABLE (MMC Transmit Excessive Deferral Packet Counter Interrupt Mask is Disabled); 1=TXEXDEFPIM_ENABLE (MMC Transmit Excessive Deferral Packet Counter Interrupt Mask is Enabled)
  [21] TXGPKTIM — MMC Transmit Good Packet Counter Interrupt Mask
    0=TXGPKTIM_DISABLE (MMC Transmit Good Packet Counter Interrupt Mask is Disabled); 1=TXGPKTIM_ENABLE (MMC Transmit Good Packet Counter Interrupt Mask is Enabled)
  [20] TXGOCTIM — MMC Transmit Good Octet Counter Interrupt Mask
    0=TXGOCTIM_DISABLE (MMC Transmit Good Octet Counter Interrupt Mask is Disabled); 1=TXGOCTIM_ENABLE (MMC Transmit Good Octet Counter Interrupt Mask is Enabled)
  [19] TXCARERPIM — MMC Transmit Carrier Error Packet Counter Interrupt Mask
    0=TXCARERPIM_DISABLE (MMC Transmit Carrier Error Packet Counter Interrupt Mask is Disabled); 1=TXCARERPIM_ENABLE (MMC Transmit Carrier Error Packet Counter Interrupt Mask is Enabled)
  [18] TXEXCOLPIM — MMC Transmit Excessive Collision Packet Counter Interrupt Mask
    0=TXEXCOLPIM_DISABLE (MMC Transmit Excessive Collision Packet Counter Interrupt Mask is Disabled); 1=TXEXCOLPIM_ENABLE (MMC Transmit Excessive Collision Packet Counter Interrupt Mask is Enabled)
  [17] TXLATCOLPIM — MMC Transmit Late Collision Packet Counter Interrupt Mask
    0=TXLATCOLPIM_DISABLE (MMC Transmit Late Collision Packet Counter Interrupt Mask is Disabled); 1=TXLATCOLPIM_ENABLE (MMC Transmit Late Collision Packet Counter Interrupt Mask is Enabled)
  [16] TXDEFPIM — MMC Transmit Deferred Packet Counter Interrupt Mask
    0=TXDEFPIM_DISABLE (MMC Transmit Deferred Packet Counter Interrupt Mask is Disabled); 1=TXDEFPIM_ENABLE (MMC Transmit Deferred Packet Counter Interrupt Mask is Enabled)
  [15] TXMCOLGPIM — MMC Transmit Multiple Collision Good Packet Counter Interrupt Mask
    0=TXMCOLGPIM_DISABLE (MMC Transmit Multiple Collision Good Packet Counter Interrupt Mask is Disabled); 1=TXMCOLGPIM_ENABLE (MMC Transmit Multiple Collision Good Packet Counter Interrupt Mask is Enabled)
  [14] TXSCOLGPIM — MMC Transmit Single Collision Good Packet Counter Interrupt Mask
    0=TXSCOLGPIM_DISABLE (MMC Transmit Single Collision Good Packet Counter Interrupt Mask is Disabled); 1=TXSCOLGPIM_ENABLE (MMC Transmit Single Collision Good Packet Counter Interrupt Mask is Enabled)
  [13] TXUFLOWERPIM — MMC Transmit Underflow Error Packet Counter Interrupt Mask
    0=TXUFLOWERPIM_DISABLE (MMC Transmit Underflow Error Packet Counter Interrupt Mask is Disabled); 1=TXUFLOWERPIM_ENABLE (MMC Transmit Underflow Error Packet Counter Interrupt Mask is Enabled)
  [12] TXBCGBPIM — MMC Transmit Broadcast Good Bad Packet Counter Interrupt Mask
    0=TXBCGBPIM_DISABLE (MMC Transmit Broadcast Good Bad Packet Counter Interrupt Mask is Disabled); 1=TXBCGBPIM_ENABLE (MMC Transmit Broadcast Good Bad Packet Counter Interrupt Mask is Enabled)
  [11] TXMCGBPIM — MMC Transmit Multicast Good Bad Packet Counter Interrupt Mask
    0=TXMCGBPIM_DISABLE (MMC Transmit Multicast Good Bad Packet Counter Interrupt Mask is Disabled); 1=TXMCGBPIM_ENABLE (MMC Transmit Multicast Good Bad Packet Counter Interrupt Mask is Enabled)
  [10] TXUCGBPIM — MMC Transmit Unicast Good Bad Packet Counter Interrupt Mask
    0=TXUCGBPIM_DISABLE (MMC Transmit Unicast Good Bad Packet Counter Interrupt Mask is Disabled); 1=TXUCGBPIM_ENABLE (MMC Transmit Unicast Good Bad Packet Counter Interrupt Mask is Enabled)
  [9] TX1024TMAXOCTGBPIM — MMC Transmit 1024 to Maximum Octet Good Bad Packet Counter Interrupt Mask
    0=TX1024TMAXOCTGBPIM_DISABLE (MMC Transmit 1024 to Maximum Octet Good Bad Packet Counter Interrupt Mask is Disabled); 1=TX1024TMAXOCTGBPIM_ENABLE (MMC Transmit 1024 to Maximum Octet Good Bad Packet Counter Interrupt Mask is Enabled)
  [8] TX512T1023OCTGBPIM — MMC Transmit 512 to 1023 Octet Good Bad Packet Counter Interrupt Mask
    0=TX512T1023OCTGBPIM_DISABLE (MMC Transmit 512 to 1023 Octet Good Bad Packet Counter Interrupt Mask is Disabled); 1=TX512T1023OCTGBPIM_ENABLE (MMC Transmit 512 to 1023 Octet Good Bad Packet Counter Interrupt Mask is Enabled)
  [7] TX256T511OCTGBPIM — MMC Transmit 256 to 511 Octet Good Bad Packet Counter Interrupt Mask
    0=TX256T511OCTGBPIM_DISABLE (MMC Transmit 256 to 511 Octet Good Bad Packet Counter Interrupt Mask is Disabled); 1=TX256T511OCTGBPIM_ENABLE (MMC Transmit 256 to 511 Octet Good Bad Packet Counter Interrupt Mask is Enabled)
  [6] TX128T255OCTGBPIM — MMC Transmit 128 to 255 Octet Good Bad Packet Counter Interrupt Mask
    0=TX128T255OCTGBPIM_DISABLE (MMC Transmit 128 to 255 Octet Good Bad Packet Counter Interrupt Mask is Disabled); 1=TX128T255OCTGBPIM_ENABLE (MMC Transmit 128 to 255 Octet Good Bad Packet Counter Interrupt Mask is Enabled)
  [5] TX65T127OCTGBPIM — MMC Transmit 65 to 127 Octet Good Bad Packet Counter Interrupt Mask
    0=TX65T127OCTGBPIM_DISABLE (MMC Transmit 65 to 127 Octet Good Bad Packet Counter Interrupt Mask is Disabled); 1=TX65T127OCTGBPIM_ENABLE (MMC Transmit 65 to 127 Octet Good Bad Packet Counter Interrupt Mask is Enabled)
  [4] TX64OCTGBPIM — MMC Transmit 64 Octet Good Bad Packet Counter Interrupt Mask
    0=TX64OCTGBPIM_DISABLE (MMC Transmit 64 Octet Good Bad Packet Counter Interrupt Mask is Disabled); 1=TX64OCTGBPIM_ENABLE (MMC Transmit 64 Octet Good Bad Packet Counter Interrupt Mask is Enabled)
  [3] TXMCGPIM — MMC Transmit Multicast Good Packet Counter Interrupt Mask
    0=TXMCGPIM_DISABLE (MMC Transmit Multicast Good Packet Counter Interrupt Mask is Disabled); 1=TXMCGPIM_ENABLE (MMC Transmit Multicast Good Packet Counter Interrupt Mask is Enabled)
  [2] TXBCGPIM — MMC Transmit Broadcast Good Packet Counter Interrupt Mask
    0=TXBCGPIM_DISABLE (MMC Transmit Broadcast Good Packet Counter Interrupt Mask is Disabled); 1=TXBCGPIM_ENABLE (MMC Transmit Broadcast Good Packet Counter Interrupt Mask is Enabled)
  [1] TXGBPKTIM — MMC Transmit Good Bad Packet Counter Interrupt Mask
    0=TXGBPKTIM_DISABLE (MMC Transmit Good Bad Packet Counter Interrupt Mask is Disabled); 1=TXGBPKTIM_ENABLE (MMC Transmit Good Bad Packet Counter Interrupt Mask is Enabled)
  [0] TXGBOCTIM — MMC Transmit Good Bad Octet Counter Interrupt Mask
    0=TXGBOCTIM_DISABLE (MMC Transmit Good Bad Octet Counter Interrupt Mask is Disabled); 1=TXGBOCTIM_ENABLE (MMC Transmit Good Bad Octet Counter Interrupt Mask is Enabled)
0x714 TX_OCNT_GB — Transmit Octet Good Bad Counter Register
  [31:0] TXOCTGB ro — Tx Octet Count Good Bad
0x718 TX_PCNT_GB — Transmit Packet Good Bad Counter Register
  [15:0] TXPKTGB ro — Tx Packet Count Good Bad
0x71C TX_BCST_PCNT_G — Transmit Broadcast Packets Good Counter Register
  [15:0] TXBCASTG ro — Tx Broadcast Packets Good
0x720 TX_MCST_PCNT_G — Transmit Multicast Packets Good Counter Register
  [15:0] TXMCASTG ro — Tx Multicast Packets Good
0x724 TX64_GB — Transmit 64 Octets Packets Good Bad Counter Register
  [15:0] TX64OCTGB ro — Tx 64Octets Packets Good_Bad
0x728 TX65TO127_GB — Transmit 65-127 Octets Packets Good Bad Counter Register
  [15:0] TX65_127OCTGB ro — Tx 65To127Octets Packets Good Bad
0x72C TX128TO255_GB — Transmit 128-255 Octets Packets Good Bad Counter Register
  [15:0] TX128_255OCTGB ro — Tx 128To255Octets Packets Good Bad
0x730 TX256TO511_GB — Transmit 256-511 Octets Packets Good Bad Counter Register
  [15:0] TX256_511OCTGB ro — Tx 256To511Octets Packets Good Bad
0x734 TX512TO1023_GB — Transmit 512-1023 Octets Packets Good Bad Counter Register
  [15:0] TX512_1023OCTGB ro — Tx 512To1023Octets Packets Good Bad
0x738 TX1024TOMAX_GB — Transmit 1024-Max Octets Packets Good Bad Counter Register
  [15:0] TX1024_MAXOCTGB ro — Tx 1024ToMaxOctets Packets Good Bad
0x73C TX_UCST_PCNT_GB — Transmit Unicast Packets Good Bad Counter Register
  [15:0] TXUCASTGB ro — Tx Unicast Packets Good Bad
0x740 TX_MCST_PCNT_GB — Transmit Multicast Packets Good Bad Counter Register
  [15:0] TXMCASTGB ro — Tx Multicast Packets Good Bad
0x744 TX_BCST_PCNT_GB — Transmit Broadcast Packets Good Bad Counter Register
  [15:0] TXBCASTGB ro — Tx Broadcast Packets Good Bad
0x748 TX_URFL_PCNT — Transmit Underflow Error Packets Counter Register
  [15:0] TXUNDRFLW ro — Tx Underflow Error Packets
0x74C TX_SNGLCOL_PCNT_G — Transmit Single Collision Packets Good Counter Register
  [15:0] TXSNGLCOLG ro — Tx Single Collision Good Packets
0x750 TX_MCOL_PCNT_G — Transmit Multiple Collision Packets Good Counter Register
  [15:0] TXMULTCOLG ro — Tx Multiple Collision Good Packets
0x754 TX_DFRD_PCNT — Transmit Deferred Packets Counter Register
  [15:0] TXDEFRD ro — Tx Deferred Packets
0x758 TX_LTCOL_PCNT — Transmit Late Collision Packets Counter Register
  [15:0] TXLATECOL ro — Tx Late Collision Packets
0x75C TX_EXCOL_PCNT — Transmit Excessive Collision Packets Counter Register
  [15:0] TXEXSCOL ro — Tx Excessive Collision Packets
0x760 TX_CRERR_PCNT — Transmit Carrier Error Packets Counter Register
  [15:0] TXCARR ro — Tx Carrier Error Packets
0x764 TX_OCNT_G — Transmit Octet Good Counter Register
  [31:0] TXOCTG ro — Tx Octet Count Good
0x768 TX_PCNT_G — Transmit Packet Good Counter Register
  [15:0] TXPKTG ro — Tx Packet Count Good
0x76C TX_EXDFRL_PCNT — Transmit Excessive Deferral Error Counter Register
  [15:0] TXEXSDEF ro — Tx Excessive Deferral Error
0x770 TX_PAUSE_PCNT — Transmit Pause Packets Counter Register
  [15:0] TXPAUSE ro — Tx Pause Packets
0x774 TX_VLAN_PCNT_G — Transmit VLAN Packets Good Counter Register
  [15:0] TXVLANG ro — Tx VLAN Packets Good
0x778 TX_OSIZE_PCNT_G — Transmit Osize Packets Good Counter Register
  [15:0] TXOSIZG ro — Tx OSize Packets Good
0x780 RX_PCNT_GB — Receive Packets Good Bad Counter Register
  [15:0] RXPKTGB ro — Rx Packets Count Good Bad
0x784 RX_OCNT_GB — Receive Octet Good Bad Counter Register
  [31:0] RXOCTGB ro — Rx Octet Count Good Bad
0x788 RX_OCNT_G — Receive Octet Good Counter Register
  [31:0] RXOCTG ro — Rx Octet Count Good
0x78C RX_BCERR_PCNT_G — Receive Broadcast Packets Good Counter Register
  [15:0] RXBCASTG ro — Rx Broadcast Packets Good
0x790 RX_MCST_PCNT_G — Receive Multicast Packets Good Counter Register
  [15:0] RXMCASTG ro — Rx Multicast Packets Good
0x794 RX_CRCERR_PCNT — Receive CRC Error Packets Counter Register
  [15:0] RXCRCERR ro — Rx CRC Error Packets
0x798 RX_ALGNERR_PCNT — Receive Alignment Error Packets Counter Register
  [15:0] RXALGNERR ro — Rx Alignment Error Packets
0x79C RX_RNTERR_PCNT — Receive Runt Error Packets Counter Register
  [15:0] RXRUNTERR ro — Rx Runt Error Packets
0x7A0 RX_JBERR_PCNT — Receive Jabber Error Packets Counter Register
  [15:0] RXJABERR ro — Rx Jabber Error Packets
